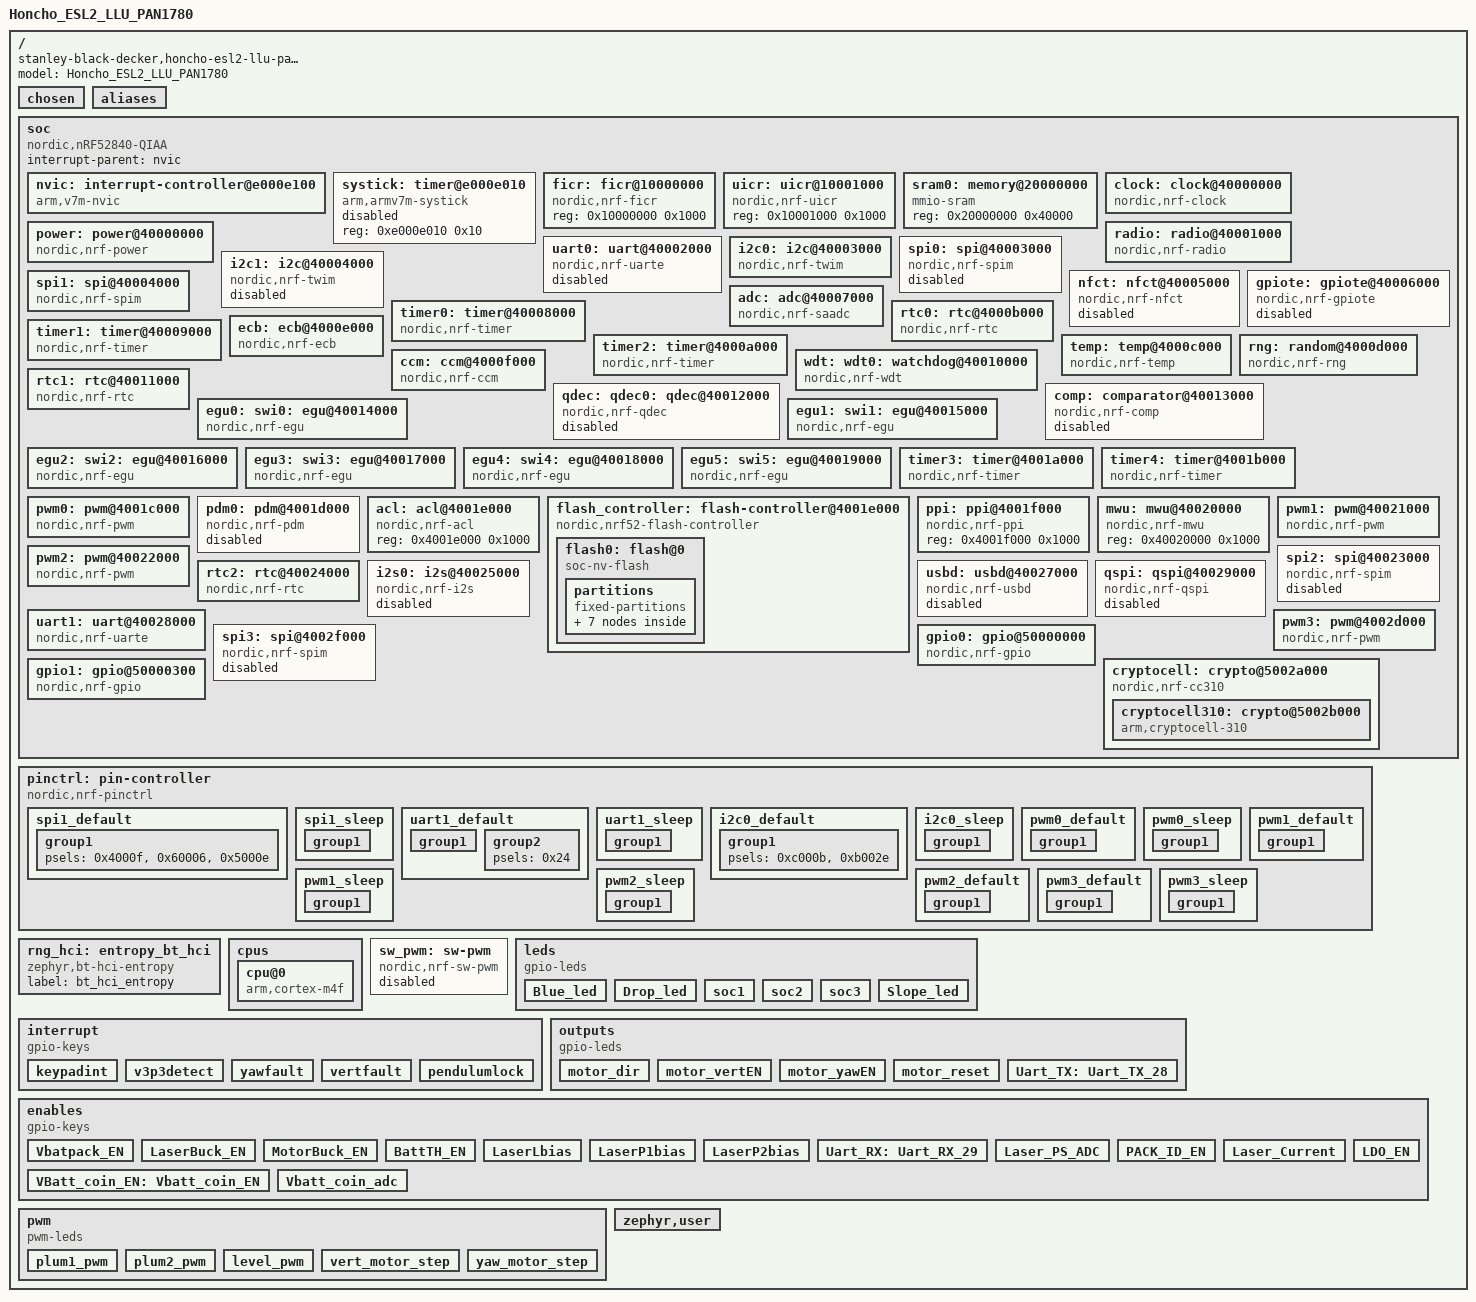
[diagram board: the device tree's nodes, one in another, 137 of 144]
/dts-v1/;

/ {
	#address-cells = < 0x1 >;
	#size-cells = < 0x1 >;
	model = "Honcho_ESL2_LLU_PAN1780";
	compatible = "stanley-black-decker,honcho-esl2-llu-pan1780";
	chosen {
		zephyr,entropy = &cryptocell;
		zephyr,flash-controller = &flash_controller;
		zephyr,sram = &sram0;
		zephyr,flash = &flash0;
		zephyr,code-partition = &slot0_partition;
	};
	aliases {
		keypadint = &keypadint;
		battdetect = &v3p3detect;
		pendlck = &pendulumlock;
		bleled = &Blue_led;
		dropled = &Drop_led;
		slopeled = &Slope_led;
		vbaten = &Vbatpack_EN;
		battthen = &BattTH_EN;
		lbucken = &LaserBuck_EN;
		mbucken = &MotorBuck_EN;
		motordir = &motor_dir;
		motorverten = &motor_vertEN;
		motoryawen = &motor_yawEN;
		lvlbias = &LaserLbias;
		plm1bias = &LaserP1bias;
		plm2bias = &LaserP2bias;
		motorrst = &motor_reset;
		uarttx = &Uart_TX;
		uartrx = &Uart_RX;
		laserpsadc = &Laser_PS_ADC;
		packiden = &PACK_ID_EN;
		vbatcoinen = &VBatt_coin_EN;
		lasercurrent = &Laser_Current;
		vbattcoinadc = &Vbatt_coin_adc;
		ldoen = &LDO_EN;
	};
	soc {
		#address-cells = < 0x1 >;
		#size-cells = < 0x1 >;
		compatible = "nordic,nRF52840-QIAA", "nordic,nRF52840", "nordic,nRF52", "simple-bus";
		interrupt-parent = < &nvic >;
		ranges;
		nvic: interrupt-controller@e000e100 {
			#address-cells = < 0x1 >;
			compatible = "arm,v7m-nvic";
			reg = < 0xe000e100 0xc00 >;
			interrupt-controller;
			#interrupt-cells = < 0x2 >;
			arm,num-irq-priority-bits = < 0x3 >;
			phandle = < 0x1 >;
		};
		systick: timer@e000e010 {
			compatible = "arm,armv7m-systick";
			reg = < 0xe000e010 0x10 >;
			status = "disabled";
		};
		ficr: ficr@10000000 {
			compatible = "nordic,nrf-ficr";
			reg = < 0x10000000 0x1000 >;
			status = "okay";
		};
		uicr: uicr@10001000 {
			compatible = "nordic,nrf-uicr";
			reg = < 0x10001000 0x1000 >;
			status = "okay";
		};
		sram0: memory@20000000 {
			compatible = "mmio-sram";
			reg = < 0x20000000 0x40000 >;
		};
		clock: clock@40000000 {
			compatible = "nordic,nrf-clock";
			reg = < 0x40000000 0x1000 >;
			interrupts = < 0x0 0x1 >;
			status = "okay";
			label = "CLOCK";
		};
		power: power@40000000 {
			compatible = "nordic,nrf-power";
			reg = < 0x40000000 0x1000 >;
			interrupts = < 0x0 0x1 >;
			status = "okay";
		};
		radio: radio@40001000 {
			compatible = "nordic,nrf-radio";
			reg = < 0x40001000 0x1000 >;
			interrupts = < 0x1 0x1 >;
			status = "okay";
			ieee802154-supported;
			ble-2mbps-supported;
			ble-coded-phy-supported;
			tx-high-power-supported;
		};
		uart0: uart@40002000 {
			compatible = "nordic,nrf-uarte";
			reg = < 0x40002000 0x1000 >;
			interrupts = < 0x2 0x1 >;
			status = "disabled";
			label = "UART_0";
		};
		i2c0: i2c@40003000 {
			compatible = "nordic,nrf-twim";
			#address-cells = < 0x1 >;
			#size-cells = < 0x0 >;
			reg = < 0x40003000 0x1000 >;
			clock-frequency = < 0x186a0 >;
			interrupts = < 0x3 0x1 >;
			status = "okay";
			label = "I2C_0";
			pinctrl-0 = < &i2c0_default >;
			pinctrl-1 = < &i2c0_sleep >;
			pinctrl-names = "default", "sleep";
		};
		spi0: spi@40003000 {
			compatible = "nordic,nrf-spim";
			#address-cells = < 0x1 >;
			#size-cells = < 0x0 >;
			reg = < 0x40003000 0x1000 >;
			interrupts = < 0x3 0x1 >;
			status = "disabled";
			label = "SPI_0";
		};
		i2c1: i2c@40004000 {
			compatible = "nordic,nrf-twim";
			#address-cells = < 0x1 >;
			#size-cells = < 0x0 >;
			reg = < 0x40004000 0x1000 >;
			clock-frequency = < 0x186a0 >;
			interrupts = < 0x4 0x1 >;
			status = "disabled";
			label = "I2C_1";
		};
		spi1: spi@40004000 {
			compatible = "nordic,nrf-spim";
			#address-cells = < 0x1 >;
			#size-cells = < 0x0 >;
			reg = < 0x40004000 0x1000 >;
			interrupts = < 0x4 0x1 >;
			status = "okay";
			label = "SPI_1";
			pinctrl-0 = < &spi1_default >;
			pinctrl-1 = < &spi1_sleep >;
			pinctrl-names = "default", "sleep";
			cs-gpios = < &gpio0 0x7 0x1 >;
		};
		nfct: nfct@40005000 {
			compatible = "nordic,nrf-nfct";
			reg = < 0x40005000 0x1000 >;
			interrupts = < 0x5 0x1 >;
			status = "disabled";
		};
		gpiote: gpiote@40006000 {
			compatible = "nordic,nrf-gpiote";
			reg = < 0x40006000 0x1000 >;
			interrupts = < 0x6 0x5 >;
			status = "disabled";
			label = "GPIOTE_0";
		};
		adc: adc@40007000 {
			compatible = "nordic,nrf-saadc";
			reg = < 0x40007000 0x1000 >;
			interrupts = < 0x7 0x1 >;
			status = "okay";
			label = "ADC_0";
			#io-channel-cells = < 0x1 >;
			phandle = < 0x17 >;
		};
		timer0: timer@40008000 {
			compatible = "nordic,nrf-timer";
			status = "okay";
			reg = < 0x40008000 0x1000 >;
			cc-num = < 0x4 >;
			interrupts = < 0x8 0x1 >;
			prescaler = < 0x0 >;
			label = "TIMER_0";
		};
		timer1: timer@40009000 {
			compatible = "nordic,nrf-timer";
			status = "okay";
			reg = < 0x40009000 0x1000 >;
			cc-num = < 0x4 >;
			interrupts = < 0x9 0x1 >;
			prescaler = < 0x0 >;
			label = "TIMER_1";
		};
		timer2: timer@4000a000 {
			compatible = "nordic,nrf-timer";
			status = "okay";
			reg = < 0x4000a000 0x1000 >;
			cc-num = < 0x4 >;
			interrupts = < 0xa 0x1 >;
			prescaler = < 0x0 >;
			label = "TIMER_2";
			phandle = < 0x11 >;
		};
		rtc0: rtc@4000b000 {
			compatible = "nordic,nrf-rtc";
			reg = < 0x4000b000 0x1000 >;
			cc-num = < 0x3 >;
			interrupts = < 0xb 0x1 >;
			status = "okay";
			clock-frequency = < 0x8000 >;
			prescaler = < 0x1 >;
			label = "RTC_0";
		};
		temp: temp@4000c000 {
			compatible = "nordic,nrf-temp";
			reg = < 0x4000c000 0x1000 >;
			interrupts = < 0xc 0x1 >;
			status = "okay";
			label = "TEMP_0";
		};
		rng: random@4000d000 {
			compatible = "nordic,nrf-rng";
			reg = < 0x4000d000 0x1000 >;
			interrupts = < 0xd 0x1 >;
			status = "okay";
			label = "RNG";
		};
		ecb: ecb@4000e000 {
			compatible = "nordic,nrf-ecb";
			reg = < 0x4000e000 0x1000 >;
			interrupts = < 0xe 0x1 >;
			status = "okay";
			label = "ECB";
		};
		ccm: ccm@4000f000 {
			compatible = "nordic,nrf-ccm";
			reg = < 0x4000f000 0x1000 >;
			interrupts = < 0xf 0x1 >;
			length-field-length-8-bits;
			status = "okay";
		};
		wdt: wdt0: watchdog@40010000 {
			compatible = "nordic,nrf-wdt";
			reg = < 0x40010000 0x1000 >;
			interrupts = < 0x10 0x1 >;
			status = "okay";
			label = "WDT";
		};
		rtc1: rtc@40011000 {
			compatible = "nordic,nrf-rtc";
			reg = < 0x40011000 0x1000 >;
			cc-num = < 0x4 >;
			interrupts = < 0x11 0x1 >;
			status = "okay";
			clock-frequency = < 0x8000 >;
			prescaler = < 0x1 >;
			label = "RTC_1";
		};
		qdec: qdec0: qdec@40012000 {
			compatible = "nordic,nrf-qdec";
			reg = < 0x40012000 0x1000 >;
			interrupts = < 0x12 0x1 >;
			status = "disabled";
			label = "QDEC";
		};
		comp: comparator@40013000 {
			compatible = "nordic,nrf-comp";
			reg = < 0x40013000 0x1000 >;
			interrupts = < 0x13 0x1 >;
			status = "disabled";
			#io-channel-cells = < 0x1 >;
		};
		egu0: swi0: egu@40014000 {
			compatible = "nordic,nrf-egu", "nordic,nrf-swi";
			reg = < 0x40014000 0x1000 >;
			interrupts = < 0x14 0x1 >;
			status = "okay";
		};
		egu1: swi1: egu@40015000 {
			compatible = "nordic,nrf-egu", "nordic,nrf-swi";
			reg = < 0x40015000 0x1000 >;
			interrupts = < 0x15 0x1 >;
			status = "okay";
		};
		egu2: swi2: egu@40016000 {
			compatible = "nordic,nrf-egu", "nordic,nrf-swi";
			reg = < 0x40016000 0x1000 >;
			interrupts = < 0x16 0x1 >;
			status = "okay";
		};
		egu3: swi3: egu@40017000 {
			compatible = "nordic,nrf-egu", "nordic,nrf-swi";
			reg = < 0x40017000 0x1000 >;
			interrupts = < 0x17 0x1 >;
			status = "okay";
		};
		egu4: swi4: egu@40018000 {
			compatible = "nordic,nrf-egu", "nordic,nrf-swi";
			reg = < 0x40018000 0x1000 >;
			interrupts = < 0x18 0x1 >;
			status = "okay";
		};
		egu5: swi5: egu@40019000 {
			compatible = "nordic,nrf-egu", "nordic,nrf-swi";
			reg = < 0x40019000 0x1000 >;
			interrupts = < 0x19 0x1 >;
			status = "okay";
		};
		timer3: timer@4001a000 {
			compatible = "nordic,nrf-timer";
			status = "okay";
			reg = < 0x4001a000 0x1000 >;
			cc-num = < 0x6 >;
			interrupts = < 0x1a 0x1 >;
			prescaler = < 0x0 >;
			label = "TIMER_3";
		};
		timer4: timer@4001b000 {
			compatible = "nordic,nrf-timer";
			status = "okay";
			reg = < 0x4001b000 0x1000 >;
			cc-num = < 0x6 >;
			interrupts = < 0x1b 0x1 >;
			prescaler = < 0x0 >;
			label = "TIMER_4";
		};
		pwm0: pwm@4001c000 {
			compatible = "nordic,nrf-pwm";
			reg = < 0x4001c000 0x1000 >;
			interrupts = < 0x1c 0x1 >;
			status = "okay";
			label = "PWM_0";
			#pwm-cells = < 0x3 >;
			pinctrl-0 = < &pwm0_default >;
			pinctrl-1 = < &pwm0_sleep >;
			pinctrl-names = "default", "sleep";
			phandle = < 0x13 >;
		};
		pdm0: pdm@4001d000 {
			compatible = "nordic,nrf-pdm";
			reg = < 0x4001d000 0x1000 >;
			interrupts = < 0x1d 0x1 >;
			status = "disabled";
			label = "PDM_0";
		};
		acl: acl@4001e000 {
			compatible = "nordic,nrf-acl";
			reg = < 0x4001e000 0x1000 >;
			status = "okay";
		};
		flash_controller: flash-controller@4001e000 {
			compatible = "nordic,nrf52-flash-controller";
			reg = < 0x4001e000 0x1000 >;
			partial-erase;
			#address-cells = < 0x1 >;
			#size-cells = < 0x1 >;
			label = "NRF_FLASH_DRV_NAME";
			flash0: flash@0 {
				compatible = "soc-nv-flash";
				label = "NRF_FLASH";
				erase-block-size = < 0x1000 >;
				write-block-size = < 0x4 >;
				reg = < 0x0 0x100000 >;
				partitions {
					compatible = "fixed-partitions";
					#address-cells = < 0x1 >;
					#size-cells = < 0x1 >;
					boot_partition: partition@0 {
						label = "mcuboot";
						reg = < 0x0 0xc000 >;
					};
					slot0_partition: partition@c000 {
						label = "image-0";
						reg = < 0xc000 0x72000 >;
					};
					scratch_partition: partition@7e000 {
						label = "image-scratch";
						reg = < 0x7e000 0x70000 >;
					};
					datalog_partition: partition@ee000 {
						label = "datalog-area";
						reg = < 0xee000 0x6000 >;
					};
					calibraion_parition: partition@f4000 {
						label = "calib-area";
						reg = < 0xf4000 0x2000 >;
					};
					variable_partition: partition@f6000 {
						label = "laserstatus-area";
						reg = < 0xf6000 0x2000 >;
					};
					storage_partition: partition@f8000 {
						label = "storage";
						reg = < 0xf8000 0x8000 >;
					};
				};
			};
		};
		ppi: ppi@4001f000 {
			compatible = "nordic,nrf-ppi";
			reg = < 0x4001f000 0x1000 >;
			status = "okay";
		};
		mwu: mwu@40020000 {
			compatible = "nordic,nrf-mwu";
			reg = < 0x40020000 0x1000 >;
			status = "okay";
		};
		pwm1: pwm@40021000 {
			compatible = "nordic,nrf-pwm";
			reg = < 0x40021000 0x1000 >;
			interrupts = < 0x21 0x1 >;
			status = "okay";
			label = "PWM_1";
			#pwm-cells = < 0x3 >;
			pinctrl-0 = < &pwm1_default >;
			pinctrl-1 = < &pwm1_sleep >;
			pinctrl-names = "default", "sleep";
			phandle = < 0x14 >;
		};
		pwm2: pwm@40022000 {
			compatible = "nordic,nrf-pwm";
			reg = < 0x40022000 0x1000 >;
			interrupts = < 0x22 0x1 >;
			status = "okay";
			label = "PWM_2";
			#pwm-cells = < 0x3 >;
			pinctrl-0 = < &pwm2_default >;
			pinctrl-1 = < &pwm2_sleep >;
			pinctrl-names = "default", "sleep";
			phandle = < 0x15 >;
		};
		spi2: spi@40023000 {
			compatible = "nordic,nrf-spim";
			#address-cells = < 0x1 >;
			#size-cells = < 0x0 >;
			reg = < 0x40023000 0x1000 >;
			interrupts = < 0x23 0x1 >;
			status = "disabled";
			label = "SPI_2";
		};
		rtc2: rtc@40024000 {
			compatible = "nordic,nrf-rtc";
			reg = < 0x40024000 0x1000 >;
			cc-num = < 0x4 >;
			interrupts = < 0x24 0x1 >;
			status = "okay";
			clock-frequency = < 0x8000 >;
			prescaler = < 0x1 >;
			label = "RTC_2";
		};
		i2s0: i2s@40025000 {
			compatible = "nordic,nrf-i2s";
			#address-cells = < 0x1 >;
			#size-cells = < 0x0 >;
			reg = < 0x40025000 0x1000 >;
			interrupts = < 0x25 0x1 >;
			status = "disabled";
			label = "I2S_0";
		};
		usbd: usbd@40027000 {
			compatible = "nordic,nrf-usbd";
			reg = < 0x40027000 0x1000 >;
			interrupts = < 0x27 0x1 >;
			num-bidir-endpoints = < 0x1 >;
			num-in-endpoints = < 0x7 >;
			num-out-endpoints = < 0x7 >;
			num-isoin-endpoints = < 0x1 >;
			num-isoout-endpoints = < 0x1 >;
			status = "disabled";
			label = "USBD";
		};
		uart1: uart@40028000 {
			compatible = "nordic,nrf-uarte";
			reg = < 0x40028000 0x1000 >;
			interrupts = < 0x28 0x1 >;
			status = "okay";
			label = "UART_1";
			current-speed = < 0x9600 >;
			pinctrl-0 = < &uart1_default >;
			pinctrl-1 = < &uart1_sleep >;
			pinctrl-names = "default", "sleep";
		};
		qspi: qspi@40029000 {
			compatible = "nordic,nrf-qspi";
			#address-cells = < 0x1 >;
			#size-cells = < 0x0 >;
			reg = < 0x40029000 0x1000 >, < 0x12000000 0x8000000 >;
			reg-names = "qspi", "qspi_mm";
			interrupts = < 0x29 0x1 >;
			status = "disabled";
			label = "QSPI";
		};
		pwm3: pwm@4002d000 {
			compatible = "nordic,nrf-pwm";
			reg = < 0x4002d000 0x1000 >;
			interrupts = < 0x2d 0x1 >;
			status = "okay";
			label = "PWM_3";
			#pwm-cells = < 0x3 >;
			pinctrl-0 = < &pwm3_default >;
			pinctrl-1 = < &pwm3_sleep >;
			pinctrl-names = "default", "sleep";
			phandle = < 0x16 >;
		};
		spi3: spi@4002f000 {
			compatible = "nordic,nrf-spim";
			#address-cells = < 0x1 >;
			#size-cells = < 0x0 >;
			reg = < 0x4002f000 0x1000 >;
			interrupts = < 0x2f 0x1 >;
			status = "disabled";
			label = "SPI_3";
		};
		gpio0: gpio@50000000 {
			compatible = "nordic,nrf-gpio";
			gpio-controller;
			reg = < 0x50000000 0x200 0x50000500 0x300 >;
			#gpio-cells = < 0x2 >;
			label = "GPIO_0";
			status = "okay";
			port = < 0x0 >;
			phandle = < 0x6 >;
		};
		gpio1: gpio@50000300 {
			compatible = "nordic,nrf-gpio";
			gpio-controller;
			reg = < 0x50000300 0x200 0x50000800 0x300 >;
			#gpio-cells = < 0x2 >;
			ngpios = < 0x10 >;
			label = "GPIO_1";
			status = "okay";
			port = < 0x1 >;
			phandle = < 0x12 >;
		};
		cryptocell: crypto@5002a000 {
			compatible = "nordic,nrf-cc310";
			reg = < 0x5002a000 0x1000 >;
			label = "CRYPTOCELL";
			status = "okay";
			#address-cells = < 0x1 >;
			#size-cells = < 0x1 >;
			cryptocell310: crypto@5002b000 {
				compatible = "arm,cryptocell-310";
				reg = < 0x5002b000 0x1000 >;
				interrupts = < 0x2a 0x1 >;
				label = "CRYPTOCELL310";
			};
		};
	};
	pinctrl: pin-controller {
		compatible = "nordic,nrf-pinctrl";
		spi1_default: spi1_default {
			phandle = < 0x4 >;
			group1 {
				psels = < 0x4000f >, < 0x60006 >, < 0x5000e >;
			};
		};
		spi1_sleep: spi1_sleep {
			phandle = < 0x5 >;
			group1 {
				psels = < 0x4000f >, < 0x60006 >, < 0x5000e >;
				low-power-enable;
			};
		};
		uart1_default: uart1_default {
			phandle = < 0xd >;
			group1 {
				psels = < 0x1002e >;
				bias-pull-up;
			};
			group2 {
				psels = < 0x24 >;
			};
		};
		uart1_sleep: uart1_sleep {
			phandle = < 0xe >;
			group1 {
				psels = < 0x1002e >, < 0x24 >;
				low-power-enable;
			};
		};
		i2c0_default: i2c0_default {
			phandle = < 0x2 >;
			group1 {
				psels = < 0xc000b >, < 0xb002e >;
			};
		};
		i2c0_sleep: i2c0_sleep {
			phandle = < 0x3 >;
			group1 {
				psels = < 0xc000b >, < 0xb002e >;
				low-power-enable;
			};
		};
		pwm0_default: pwm0_default {
			phandle = < 0x7 >;
			group1 {
				psels = < 0x160029 >;
				nordic,invert;
			};
		};
		pwm0_sleep: pwm0_sleep {
			phandle = < 0x8 >;
			group1 {
				psels = < 0x160029 >;
				low-power-enable;
			};
		};
		pwm1_default: pwm1_default {
			phandle = < 0x9 >;
			group1 {
				psels = < 0x16002d >;
				nordic,invert;
			};
		};
		pwm1_sleep: pwm1_sleep {
			phandle = < 0xa >;
			group1 {
				psels = < 0x16002d >;
				low-power-enable;
			};
		};
		pwm2_default: pwm2_default {
			phandle = < 0xb >;
			group1 {
				psels = < 0x160028 >;
				nordic,invert;
			};
		};
		pwm2_sleep: pwm2_sleep {
			phandle = < 0xc >;
			group1 {
				psels = < 0x160028 >;
				low-power-enable;
			};
		};
		pwm3_default: pwm3_default {
			phandle = < 0xf >;
			group1 {
				psels = < 0x160026 >, < 0x170022 >;
				nordic,invert;
			};
		};
		pwm3_sleep: pwm3_sleep {
			phandle = < 0x10 >;
			group1 {
				psels = < 0x160026 >, < 0x170022 >;
				low-power-enable;
			};
		};
	};
	rng_hci: entropy_bt_hci {
		compatible = "zephyr,bt-hci-entropy";
		label = "bt_hci_entropy";
		status = "okay";
	};
	cpus {
		#address-cells = < 0x1 >;
		#size-cells = < 0x0 >;
		cpu@0 {
			device_type = "cpu";
			compatible = "arm,cortex-m4f";
			reg = < 0x0 >;
			swo-ref-frequency = < 0x1e84800 >;
		};
	};
	sw_pwm: sw-pwm {
		compatible = "nordic,nrf-sw-pwm";
		status = "disabled";
		label = "SW_PWM";
		generator = < &timer2 >;
		clock-prescaler = < 0x0 >;
		#pwm-cells = < 0x3 >;
	};
	leds {
		compatible = "gpio-leds";
		Blue_led: Blue_led {
			gpios = < &gpio0 0x8 0x1 >;
			label = "BLE LED blue";
		};
		Drop_led: Drop_led {
			gpios = < &gpio0 0xd 0x1 >;
			label = "Drop LED";
		};
		soc1: soc1 {
			gpios = < &gpio0 0x10 0x1 >;
			label = "Battery SOC 1";
		};
		soc2: soc2 {
			gpios = < &gpio0 0x18 0x1 >;
			label = "Battery SOC 2";
		};
		soc3: soc3 {
			gpios = < &gpio0 0x17 0x1 >;
			label = "Battery SOC 3";
		};
		Slope_led: Slope_led {
			gpios = < &gpio1 0x7 0x1 >;
			label = "Pendulum Slope Indication LED";
		};
	};
	interrupt {
		compatible = "gpio-keys";
		keypadint: keypadint {
			gpios = < &gpio0 0x14 0x20 >;
			label = "INT 1 from attiny";
		};
		v3p3detect: v3p3detect {
			gpios = < &gpio0 0xc 0x0 >;
			label = "3.3v LDO detection";
		};
		yawfault: yawfault {
			gpios = < &gpio0 0x15 0x0 >;
			label = "Fault for yaw motor driver";
		};
		vertfault: vertfault {
			gpios = < &gpio1 0xf 0x0 >;
			label = "Fault for vertical motor driver";
		};
		pendulumlock: pendulumlock {
			gpios = < &gpio0 0x4 0x20 >;
			label = "Pendulum lock switch for slope LED";
		};
	};
	outputs {
		compatible = "gpio-leds";
		motor_dir: motor_dir {
			gpios = < &gpio1 0xa 0x0 >;
			label = "Vertical Motor Direction pin";
		};
		motor_vertEN: motor_vertEN {
			gpios = < &gpio1 0xc 0x0 >;
			label = "Enable vertical motor driver";
		};
		motor_yawEN: motor_yawEN {
			gpios = < &gpio1 0xb 0x0 >;
			label = "Enable Yaw motor driver";
		};
		motor_reset: motor_reset {
			gpios = < &gpio1 0x5 0x0 >;
			label = "Motor driver reset pin";
		};
		Uart_TX: Uart_TX_28 {
			gpios = < &gpio0 0x1c 0x0 >;
			label = "UART TX";
		};
	};
	enables {
		compatible = "gpio-keys";
		Vbatpack_EN: Vbatpack_EN {
			gpios = < &gpio0 0x11 0x0 >;
			label = "Battery enable for volatge measurement";
		};
		LaserBuck_EN: LaserBuck_EN {
			gpios = < &gpio0 0x19 0x0 >;
			label = "Lasre buck converter Enable 8V";
		};
		MotorBuck_EN: MotorBuck_EN {
			gpios = < &gpio1 0x1 0x0 >;
			label = "Motor Buck Convertor Enable 14V";
		};
		BattTH_EN: BattTH_EN {
			gpios = < &gpio0 0x3 0x0 >;
			label = "Btthery Thermistor enable";
		};
		LaserLbias: LaserLbias {
			gpios = < &gpio1 0x4 0x0 >;
			label = "Bias current enable for level laser";
		};
		LaserP1bias: LaserP1bias {
			gpios = < &gpio1 0x3 0x0 >;
			label = "Bias current enable for plum 1 laser";
		};
		LaserP2bias: LaserP2bias {
			gpios = < &gpio0 0x13 0x0 >;
			label = "Bias current enable for plum 2 laser";
		};
		Uart_RX: Uart_RX_29 {
			gpios = < &gpio0 0x1d 0x0 >;
			label = "UART RX";
		};
		Laser_PS_ADC: Laser_PS_ADC {
			gpios = < &gpio0 0x5 0x0 >;
			label = "LASERPSASDC";
		};
		PACK_ID_EN: PACK_ID_EN {
			gpios = < &gpio0 0x1a 0x0 >;
			label = "pack ID";
		};
		VBatt_coin_EN: Vbatt_coin_EN {
			gpios = < &gpio0 0x1b 0x0 >;
			label = "coin adc en";
		};
		Laser_Current: Laser_Current {
			gpios = < &gpio0 0x1e 0x0 >;
			label = "laser cuurent";
		};
		Vbatt_coin_adc: Vbatt_coin_adc {
			gpios = < &gpio0 0x1f 0x0 >;
			label = "coin adc";
		};
		LDO_EN: LDO_EN {
			gpios = < &gpio0 0x16 0x0 >;
			label = "LDO enable";
		};
	};
	pwm {
		compatible = "pwm-leds";
		plum1_pwm: plum1_pwm {
			pwms = < &pwm0 0x0 0x1312d00 0x1 >;
			label = "PWM control for plum1 laser";
		};
		plum2_pwm: plum2_pwm {
			pwms = < &pwm1 0x0 0x1312d00 0x1 >;
			label = "PWM control for plum2 laser";
		};
		level_pwm: level_pwm {
			pwms = < &pwm2 0x0 0x1312d00 0x1 >;
			label = "PWM control for level laser";
		};
		vert_motor_step: vert_motor_step {
			pwms = < &pwm3 0x0 0x1312d00 0x1 >;
			label = "PWM control for Vertical motor";
		};
		yaw_motor_step: yaw_motor_step {
			pwms = < &pwm3 0x1 0x1312d00 0x1 >;
			label = "PWM control for Yaw motor";
		};
	};
	zephyr,user {
		io-channels = < &adc 0x0 >, < &adc 0x5 >, < &adc 0x6 >, < &adc 0x7 >;
	};
};
